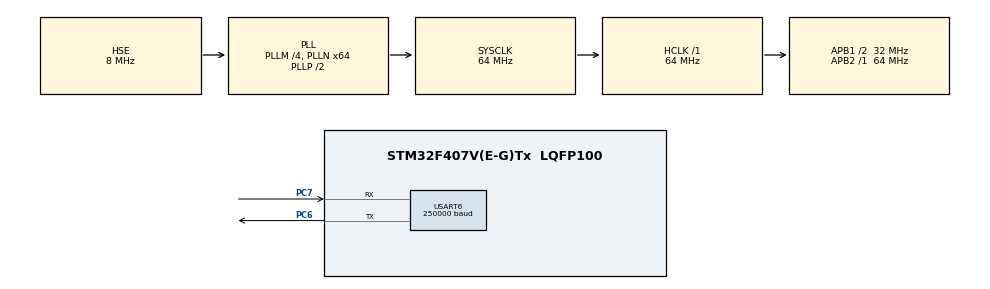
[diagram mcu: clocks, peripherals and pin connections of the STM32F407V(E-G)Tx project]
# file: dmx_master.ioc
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Mcu.Family=STM32F4
Mcu.Name=STM32F407V(E-G)Tx
Mcu.Package=LQFP100
NVIC.PriorityGroup=NVIC_PRIORITYGROUP_4
PC6.Mode=Asynchronous
PC6.Signal=USART6_TX
PC7.Mode=Asynchronous
PC7.Signal=USART6_RX
PH0-OSC_IN.Mode=HSE-External-Oscillator
PH0-OSC_IN.Signal=RCC_OSC_IN
PH1-OSC_OUT.Mode=HSE-External-Oscillator
PH1-OSC_OUT.Signal=RCC_OSC_OUT
ProjectManager.HeapSize=0x200
ProjectManager.StackSize=0x400
ProjectManager.TargetToolchain=MDK-ARM V5
RCC.48MHZClocksFreq_Value=32000000
RCC.AHBFreq_Value=64000000
RCC.APB1CLKDivider=RCC_HCLK_DIV2
RCC.APB1Freq_Value=32000000
RCC.APB1TimFreq_Value=64000000
RCC.APB2Freq_Value=64000000
RCC.APB2TimFreq_Value=64000000
RCC.CortexFreq_Value=64000000
RCC.HCLKFreq_Value=64000000
RCC.HSE_VALUE=8000000
RCC.HSI_VALUE=16000000
RCC.LSE_VALUE=32768
RCC.PLLM=4
RCC.PLLN=64
RCC.PLLSourceVirtual=RCC_PLLSOURCE_HSE
RCC.SYSCLKFreq_VALUE=64000000
RCC.SYSCLKSource=RCC_SYSCLKSOURCE_PLLCLK
RCC.VCOOutputFreq_Value=128000000
USART6.BaudRate=250000
USART6.StopBits=STOPBITS_2
USART6.VirtualMode=VM_ASYNC
board=dmx_master

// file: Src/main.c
/**
  ******************************************************************************
  * File Name          : main.c
  * Description        : Main program body
  ******************************************************************************
  ** This notice applies to any and all portions of this file
  * that are not between comment pairs USER CODE BEGIN and
  * USER CODE END. Other portions of this file, whether
  * inserted by the user or by software development tools
  * are owned by their respective copyright owners.
  *
  * COPYRIGHT(c) 2017 STMicroelectronics
  *
  * Redistribution and use in source and binary forms, with or without modification,
  * are permitted provided that the following conditions are met:
  *   1. Redistributions of source code must retain the above copyright notice,
  *      this list of conditions and the following disclaimer.
  *   2. Redistributions in binary form must reproduce the above copyright notice,
  *      this list of conditions and the following disclaimer in the documentation
  *      and/or other materials provided with the distribution.
  *   3. Neither the name of STMicroelectronics nor the names of its contributors
  *      may be used to endorse or promote products derived from this software
  *      without specific prior written permission.
  *
  * THIS SOFTWARE IS PROVIDED BY THE COPYRIGHT HOLDERS AND CONTRIBUTORS "AS IS"
  * AND ANY EXPRESS OR IMPLIED WARRANTIES, INCLUDING, BUT NOT LIMITED TO, THE
  * IMPLIED WARRANTIES OF MERCHANTABILITY AND FITNESS FOR A PARTICULAR PURPOSE ARE
  * DISCLAIMED. IN NO EVENT SHALL THE COPYRIGHT HOLDER OR CONTRIBUTORS BE LIABLE
  * FOR ANY DIRECT, INDIRECT, INCIDENTAL, SPECIAL, EXEMPLARY, OR CONSEQUENTIAL
  * DAMAGES (INCLUDING, BUT NOT LIMITED TO, PROCUREMENT OF SUBSTITUTE GOODS OR
  * SERVICES; LOSS OF USE, DATA, OR PROFITS; OR BUSINESS INTERRUPTION) HOWEVER
  * CAUSED AND ON ANY THEORY OF LIABILITY, WHETHER IN CONTRACT, STRICT LIABILITY,
  * OR TORT (INCLUDING NEGLIGENCE OR OTHERWISE) ARISING IN ANY WAY OUT OF THE USE
  * OF THIS SOFTWARE, EVEN IF ADVISED OF THE POSSIBILITY OF SUCH DAMAGE.
  *
  ******************************************************************************
  */
#include "main.h"
#include "stm32f4xx_hal.h"

/* USER CODE BEGIN Includes */

#include "tm_stm32_delay.h"
#include <string.h>
#include <stdlib.h>

/* USER CODE END Includes */

UART_HandleTypeDef huart6;

/* USER CODE BEGIN PV */
/* Private variables ---------------------------------------------------------*/

unsigned char DMXBuff[513];
int i;

/* USER CODE END PV */

void SystemClock_Config(void);
static void MX_GPIO_Init(void);
static void MX_USART6_UART_Init(void);

/* USER CODE BEGIN PFP */
/* Private function prototypes -----------------------------------------------*/

static void GPIO6_ModeGPIO(void);
static void GPIO6_ModeUART(void);

/* USER CODE END PFP */

int main(void)
{

  /* MCU Configuration----------------------------------------------------------*/

  /* Reset of all peripherals, Initializes the Flash interface and the Systick. */
  HAL_Init();

  /* Configure the system clock */
  SystemClock_Config();

  /* Initialize all configured peripherals */
  MX_GPIO_Init();
  MX_USART6_UART_Init();

  /* USER CODE BEGIN 2 */

	DMXBuff[0]=0x00;
	strcpy((char *)DMXBuff+1,"Brit-kommanda! Britantsy o shotlandtsy na kuratorstve! 8(xxx)xxx-xx-xx");

  /* USER CODE END 2 */

  /* Infinite loop */
  /* USER CODE BEGIN WHILE */
  while (1)
  {
		GPIO6_ModeGPIO();
		HAL_GPIO_WritePin(GPIOC,GPIO_PIN_6,GPIO_PIN_RESET); // BREAK 174 uS
		Delay(150);
		HAL_GPIO_WritePin(GPIOC,GPIO_PIN_6,GPIO_PIN_SET); // MAB 14 uS
    Delay(14);

		GPIO6_ModeUART();

		for(i=0;i<=512;i++)
		{
			HAL_UART_Transmit(&huart6,(void *)&DMXBuff[i],sizeof(unsigned char),10);
		}

		Delay(1000);
		//HAL_Delay(1);

  /* USER CODE END WHILE */

  }

}

/** System Clock Configuration
*/
void SystemClock_Config(void)
{

  RCC_OscInitTypeDef RCC_OscInitStruct;
  RCC_ClkInitTypeDef RCC_ClkInitStruct;

    /**Configure the main internal regulator output voltage
    */
  __HAL_RCC_PWR_CLK_ENABLE();

  __HAL_PWR_VOLTAGESCALING_CONFIG(PWR_REGULATOR_VOLTAGE_SCALE1);

    /**Initializes the CPU, AHB and APB busses clocks
    */
  RCC_OscInitStruct.OscillatorType = RCC_OSCILLATORTYPE_HSE;
  RCC_OscInitStruct.HSEState = RCC_HSE_ON;
  RCC_OscInitStruct.PLL.PLLState = RCC_PLL_ON;
  RCC_OscInitStruct.PLL.PLLSource = RCC_PLLSOURCE_HSE;
  RCC_OscInitStruct.PLL.PLLM = 4;
  RCC_OscInitStruct.PLL.PLLN = 64;
  RCC_OscInitStruct.PLL.PLLP = RCC_PLLP_DIV2;
  RCC_OscInitStruct.PLL.PLLQ = 4;
  if (HAL_RCC_OscConfig(&RCC_OscInitStruct) != HAL_OK)
  {
    _Error_Handler(__FILE__, __LINE__);
  }

    /**Initializes the CPU, AHB and APB busses clocks
    */
  RCC_ClkInitStruct.ClockType = RCC_CLOCKTYPE_HCLK|RCC_CLOCKTYPE_SYSCLK
                              |RCC_CLOCKTYPE_PCLK1|RCC_CLOCKTYPE_PCLK2;
  RCC_ClkInitStruct.SYSCLKSource = RCC_SYSCLKSOURCE_PLLCLK;
  RCC_ClkInitStruct.AHBCLKDivider = RCC_SYSCLK_DIV1;
  RCC_ClkInitStruct.APB1CLKDivider = RCC_HCLK_DIV2;
  RCC_ClkInitStruct.APB2CLKDivider = RCC_HCLK_DIV1;

  if (HAL_RCC_ClockConfig(&RCC_ClkInitStruct, FLASH_LATENCY_2) != HAL_OK)
  {
    _Error_Handler(__FILE__, __LINE__);
  }

    /**Configure the Systick interrupt time
    */
  HAL_SYSTICK_Config(HAL_RCC_GetHCLKFreq()/1000);

    /**Configure the Systick
    */
  HAL_SYSTICK_CLKSourceConfig(SYSTICK_CLKSOURCE_HCLK);

  /* SysTick_IRQn interrupt configuration */
  HAL_NVIC_SetPriority(SysTick_IRQn, 0, 0);
}

/* USART6 init function */
static void MX_USART6_UART_Init(void)
{

  huart6.Instance = USART6;
  huart6.Init.BaudRate = 250000;
  huart6.Init.WordLength = UART_WORDLENGTH_8B;
  huart6.Init.StopBits = UART_STOPBITS_2;
  huart6.Init.Parity = UART_PARITY_NONE;
  huart6.Init.Mode = UART_MODE_TX_RX;
  huart6.Init.HwFlowCtl = UART_HWCONTROL_NONE;
  huart6.Init.OverSampling = UART_OVERSAMPLING_16;
  if (HAL_UART_Init(&huart6) != HAL_OK)
  {
    _Error_Handler(__FILE__, __LINE__);
  }

}

/** Configure pins as
        * Analog
        * Input
        * Output
        * EVENT_OUT
        * EXTI
*/
static void MX_GPIO_Init(void)
{

  /* GPIO Ports Clock Enable */
  __HAL_RCC_GPIOH_CLK_ENABLE();
  __HAL_RCC_GPIOC_CLK_ENABLE();

}

/* USER CODE BEGIN 4 */

static void GPIO6_ModeGPIO(void)
{
	HAL_UART_DeInit(&huart6);

	GPIO_InitTypeDef GPIO_InitStruct;

  /*Configure GPIO pin : PC6 */
  GPIO_InitStruct.Pin = GPIO_PIN_6;
  GPIO_InitStruct.Mode = GPIO_MODE_OUTPUT_PP;
  GPIO_InitStruct.Pull = GPIO_PULLUP;
  GPIO_InitStruct.Speed = GPIO_SPEED_FREQ_HIGH;
  HAL_GPIO_Init(GPIOC, &GPIO_InitStruct);

//HAL_UART_DeInit(&huart6);

//GPIOC->MODER |= 0x1000; //PC6 - GPIO выход
//GPIOC->MODER &= ~0x2000;
//
//GPIOC->PUPDR |= 0x1000; //Пуллап
//GPIOC->PUPDR &= ~0x2000;
//
//GPIOC->OSPEEDR |= 0x3000; // Высокая скорость

}

static void GPIO6_ModeUART(void)
{
	GPIO_InitTypeDef GPIO_InitStruct;

  /*Configure GPIO pin : PC6 */
  GPIO_InitStruct.Pin = GPIO_PIN_6;
  GPIO_InitStruct.Mode = GPIO_MODE_AF_PP;
  GPIO_InitStruct.Pull = GPIO_PULLUP;
  GPIO_InitStruct.Speed = GPIO_SPEED_FREQ_HIGH;
  HAL_GPIO_Init(GPIOC, &GPIO_InitStruct);

//	GPIOC->MODER &= ~0x1000; //PC6 - GPIO выход
//  GPIOC->MODER |= 0x2000;
//
//  GPIOC->PUPDR |= 0x1000; //Пуллап
//  GPIOC->PUPDR &= ~0x2000;
//
//  GPIOC->OSPEEDR |= 0x3000; // Высокая скорость

	MX_USART6_UART_Init();

}

/* USER CODE END 4 */

void _Error_Handler(char * file, int line)
{
  while(1)
  {
  }
}

/************************ (C) COPYRIGHT STMicroelectronics *****END OF FILE****/
